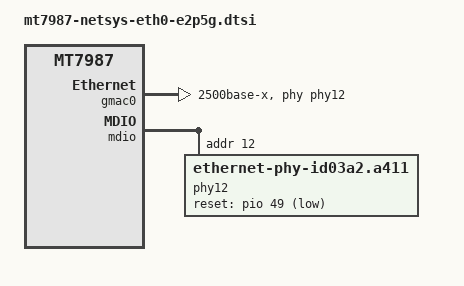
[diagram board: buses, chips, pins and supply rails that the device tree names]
// SPDX-License-Identifier: (GPL-2.0 OR MIT)

&eth {
	gmac0: mac@0 {
		compatible = "mediatek,eth-mac";
		reg = <0>;
		pcs-handle = <&sgmiipcs0>;
		phy-mode = "2500base-x";
		phy-handle = <&phy12>;
	};
};

&mdio {
	phy12: phy@12 {
		compatible = "ethernet-phy-id03a2.a411";
		reg = <12>;
		reset-gpios = <&pio 49 1>;
		reset-assert-us = <10000>;
		reset-deassert-us = <10000>;
		phy-mode = "2500base-x";
		full-duplex;
		pause;
		airoha,polarity = <1>;
		airoha,surge = <0>;
		airoha,phy-handle;
	};
};

&hnat {
	mtketh-lan = "eth0";
};
